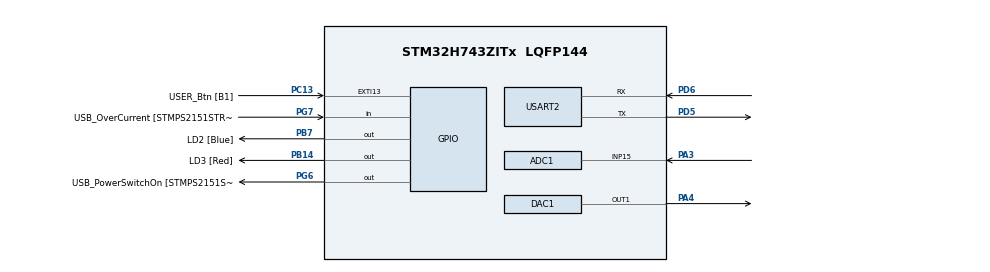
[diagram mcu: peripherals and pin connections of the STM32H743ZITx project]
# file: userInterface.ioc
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ADC1.Channel-28\#ChannelRegularConversion=ADC_CHANNEL_15
ADC1.NbrOfConversionFlag=1
ADC1.OffsetNumber-28\#ChannelRegularConversion=ADC_OFFSET_NONE
ADC1.Rank-28\#ChannelRegularConversion=1
ADC1.Resolution=ADC_RESOLUTION_8B
ADC1.SamplingTime-28\#ChannelRegularConversion=ADC_SAMPLETIME_1CYCLE_5
ADC1.master=1
DAC1.DAC_Trigger-DAC_OUT1=DAC_TRIGGER_T6_TRGO
Dma.DAC1_CH1.0.Direction=DMA_MEMORY_TO_PERIPH
Dma.DAC1_CH1.0.EventEnable=DISABLE
Dma.DAC1_CH1.0.FIFOMode=DMA_FIFOMODE_ENABLE
Dma.DAC1_CH1.0.FIFOThreshold=DMA_FIFO_THRESHOLD_FULL
Dma.DAC1_CH1.0.Instance=DMA1_Stream0
Dma.DAC1_CH1.0.MemBurst=DMA_MBURST_SINGLE
Dma.DAC1_CH1.0.MemDataAlignment=DMA_MDATAALIGN_HALFWORD
Dma.DAC1_CH1.0.MemInc=DMA_MINC_ENABLE
Dma.DAC1_CH1.0.Mode=DMA_CIRCULAR
Dma.DAC1_CH1.0.PeriphBurst=DMA_PBURST_SINGLE
Dma.DAC1_CH1.0.PeriphDataAlignment=DMA_PDATAALIGN_HALFWORD
Dma.DAC1_CH1.0.PeriphInc=DMA_PINC_DISABLE
Dma.DAC1_CH1.0.Polarity=HAL_DMAMUX_REQ_GEN_RISING
Dma.DAC1_CH1.0.Priority=DMA_PRIORITY_LOW
Dma.DAC1_CH1.0.RequestNumber=1
Dma.DAC1_CH1.0.SyncEnable=DISABLE
Dma.DAC1_CH1.0.SyncPolarity=HAL_DMAMUX_SYNC_NO_EVENT
Dma.DAC1_CH1.0.SyncRequestNumber=1
Dma.Request0=DAC1_CH1
FREERTOS.Queues01=queueCLI,32,uint8_t,0,Dynamic,NULL,NULL
FREERTOS.Tasks01=defaultTask,0,128,StartDefaultTask,Default,NULL,Dynamic,NULL,NULL;consoleTask,-2,128,StartConsoleTask,As weak,NULL,Dynamic,NULL,NULL;adc3Task,0,128,StartAdc1Task,As weak,NULL,Dynamic,NULL,NULL;dac1Task,-2,256,StartDac1Task,As weak,NULL,Dynamic,NULL,NULL
FREERTOS.configCHECK_FOR_STACK_OVERFLOW=1
FREERTOS.configUSE_MALLOC_FAILED_HOOK=1
Mcu.Family=STM32H7
Mcu.Name=STM32H743ZITx
Mcu.Package=LQFP144
NVIC.DMA1_Stream0_IRQn=true\:5\:0\:false\:false\:true\:true\:false
NVIC.PriorityGroup=NVIC_PRIORITYGROUP_4
NVIC.TIM1_UP_IRQn=true\:0\:0\:false\:false\:true\:false\:false
NVIC.TimeBase=TIM1_UP_IRQn
NVIC.TimeBaseIP=TIM1
NVIC.USART2_IRQn=true\:5\:0\:false\:false\:true\:true\:true
PA3.Signal=ADCx_INP15
PA4.Signal=COMP_DAC11_group
PB14.GPIO_Label=LD3 [Red]
PB14.Signal=GPIO_Output
PB7.GPIO_Label=LD2 [Blue]
PB7.Signal=GPIO_Output
PC13.GPIO_Label=USER_Btn [B1]
PC13.Signal=GPXTI13
PC3_C.Signal=ADC3_INP1
PD5.Mode=Asynchronous
PD5.Signal=USART2_TX
PD6.Mode=Asynchronous
PD6.Signal=USART2_RX
PG6.GPIO_Label=USB_PowerSwitchOn [STMPS2151STR_EN]
PG6.Signal=GPIO_Output
PG7.GPIO_Label=USB_OverCurrent [STMPS2151STR_FAULT]
PG7.Signal=GPIO_Input
ProjectManager.HeapSize=0x200
ProjectManager.StackSize=0x400
ProjectManager.TargetToolchain=TrueSTUDIO
RCC.48MHZClocksFreq_Value=24000000
RCC.ADCFreq_Value=129000000
RCC.AHBFreq_Value=216000000
RCC.APB1CLKDivider=RCC_HCLK_DIV4
RCC.APB1Freq_Value=80000000
RCC.APB1TimFreq_Value=108000000
RCC.APB2CLKDivider=RCC_HCLK_DIV2
RCC.APB2Freq_Value=80000000
RCC.APB2TimFreq_Value=216000000
RCC.APB3Freq_Value=80000000
RCC.APB4Freq_Value=80000000
RCC.CortexFreq_Value=80000000
RCC.DIVM1=4
RCC.DIVN1=10
RCC.DIVQ1=4
RCC.HCLKFreq_Value=80000000
RCC.HSE_VALUE=8000000
RCC.HSI_VALUE=64000000
RCC.PLLM=25
RCC.PLLMUL=RCC_PLL_MUL9
RCC.PLLN=432
RCC.PLLQ=9
RCC.PRESCALERUSB=RCC_USBCLKSOURCE_PLL_DIV1_5
RCC.SYSCLKFreq_VALUE=80000000
RCC.SYSCLKSource=RCC_SYSCLKSOURCE_PLLCLK
RCC.SYSCLKSourceVirtual=RCC_SYSCLKSOURCE_PLLCLK
RCC.USBFreq_Value=40000000
RCC.VCOOutputFreq_Value=432000000
SH.ADCx_INP15.0=ADC1_INP15,IN15-Single-Ended
SH.COMP_DAC11_group.0=DAC1_OUT1,DAC_OUT1
TIM6.Period=32
TIM6.TIM_MasterOutputTrigger=TIM_TRGO_UPDATE
USART2.VirtualMode-Asynchronous=VM_ASYNC
VP_FREERTOS_VS_ENABLE.Mode=Enabled
VP_SYS_VS_tim1.Mode=TIM1
VP_TIM6_VS_ClockSourceINT.Mode=Enable_Timer
board=NUCLEO-H743ZI

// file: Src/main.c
/**
  ******************************************************************************
  * @file           : main.c
  * @brief          : Main program body
  ******************************************************************************
  * This notice applies to any and all portions of this file
  * that are not between comment pairs USER CODE BEGIN and
  * USER CODE END. Other portions of this file, whether
  * inserted by the user or by software development tools
  * are owned by their respective copyright owners.
  *
  * Copyright (c) 2018 STMicroelectronics International N.V.
  * All rights reserved.
  *
  * Redistribution and use in source and binary forms, with or without
  * modification, are permitted, provided that the following conditions are met:
  *
  * 1. Redistribution of source code must retain the above copyright notice,
  *    this list of conditions and the following disclaimer.
  * 2. Redistributions in binary form must reproduce the above copyright notice,
  *    this list of conditions and the following disclaimer in the documentation
  *    and/or other materials provided with the distribution.
  * 3. Neither the name of STMicroelectronics nor the names of other
  *    contributors to this software may be used to endorse or promote products
  *    derived from this software without specific written permission.
  * 4. This software, including modifications and/or derivative works of this
  *    software, must execute solely and exclusively on microcontroller or
  *    microprocessor devices manufactured by or for STMicroelectronics.
  * 5. Redistribution and use of this software other than as permitted under
  *    this license is void and will automatically terminate your rights under
  *    this license.
  *
  * THIS SOFTWARE IS PROVIDED BY STMICROELECTRONICS AND CONTRIBUTORS "AS IS"
  * AND ANY EXPRESS, IMPLIED OR STATUTORY WARRANTIES, INCLUDING, BUT NOT
  * LIMITED TO, THE IMPLIED WARRANTIES OF MERCHANTABILITY, FITNESS FOR A
  * PARTICULAR PURPOSE AND NON-INFRINGEMENT OF THIRD PARTY INTELLECTUAL PROPERTY
  * RIGHTS ARE DISCLAIMED TO THE FULLEST EXTENT PERMITTED BY LAW. IN NO EVENT
  * SHALL STMICROELECTRONICS OR CONTRIBUTORS BE LIABLE FOR ANY DIRECT, INDIRECT,
  * INCIDENTAL, SPECIAL, EXEMPLARY, OR CONSEQUENTIAL DAMAGES (INCLUDING, BUT NOT
  * LIMITED TO, PROCUREMENT OF SUBSTITUTE GOODS OR SERVICES; LOSS OF USE, DATA,
  * OR PROFITS; OR BUSINESS INTERRUPTION) HOWEVER CAUSED AND ON ANY THEORY OF
  * LIABILITY, WHETHER IN CONTRACT, STRICT LIABILITY, OR TORT (INCLUDING
  * NEGLIGENCE OR OTHERWISE) ARISING IN ANY WAY OUT OF THE USE OF THIS SOFTWARE,
  * EVEN IF ADVISED OF THE POSSIBILITY OF SUCH DAMAGE.
  *
  ******************************************************************************
  */
#include "main.h"
#include "stm32h7xx_hal.h"
#include "cmsis_os.h"

/* USER CODE BEGIN Includes */
#include <stdio.h>
#include <string.h>
#include "consoleIO.h"

/* USER CODE END Includes */

ADC_HandleTypeDef hadc1;

DAC_HandleTypeDef hdac1;
DMA_HandleTypeDef hdma_dac1_ch1;

TIM_HandleTypeDef htim6;

UART_HandleTypeDef huart2;

osThreadId defaultTaskHandle;
osThreadId consoleTaskHandle;
osThreadId adc3TaskHandle;
osThreadId dac1TaskHandle;
osMessageQId queueCLIHandle;

/* USER CODE BEGIN PV */
/* Private variables ---------------------------------------------------------*/

/* USER CODE END PV */

void SystemClock_Config(void);
static void MX_GPIO_Init(void);
static void MX_DMA_Init(void);
static void MX_USART2_UART_Init(void);
static void MX_DAC1_Init(void);
static void MX_ADC1_Init(void);
static void MX_TIM6_Init(void);
void StartDefaultTask(void const * argument);
void StartConsoleTask(void const * argument);
void StartAdc1Task(void const * argument);
void StartDac1Task(void const * argument);

/* USER CODE BEGIN PFP */
/* Private function prototypes -----------------------------------------------*/

/* USER CODE END PFP */

int main(void)
{

  /* MCU Configuration----------------------------------------------------------*/

  /* Reset of all peripherals, Initializes the Flash interface and the Systick. */
  HAL_Init();

  /* USER CODE BEGIN Init */
	consoleInit();

  /* USER CODE END Init */

  /* Configure the system clock */
  SystemClock_Config();

  /* Initialize all configured peripherals */
  MX_GPIO_Init();
  MX_DMA_Init();
  MX_USART2_UART_Init();
  MX_DAC1_Init();
  MX_ADC1_Init();
  MX_TIM6_Init();
  /* USER CODE BEGIN 2 */
	StartConsoleIO();

  /* USER CODE END 2 */

  /* Create the thread(s) */
  /* definition and creation of defaultTask */
  osThreadDef(defaultTask, StartDefaultTask, osPriorityNormal, 0, 128);
  defaultTaskHandle = osThreadCreate(osThread(defaultTask), NULL);

  /* definition and creation of consoleTask */
  osThreadDef(consoleTask, StartConsoleTask, osPriorityLow, 0, 128);
  consoleTaskHandle = osThreadCreate(osThread(consoleTask), NULL);

  /* definition and creation of adc3Task */
  osThreadDef(adc3Task, StartAdc1Task, osPriorityNormal, 0, 128);
  adc3TaskHandle = osThreadCreate(osThread(adc3Task), NULL);

  /* definition and creation of dac1Task */
  osThreadDef(dac1Task, StartDac1Task, osPriorityLow, 0, 256);
  dac1TaskHandle = osThreadCreate(osThread(dac1Task), NULL);

  /* Create the queue(s) */
  /* definition and creation of queueCLI */
/* what about the sizeof here??? cd native code */
  osMessageQDef(queueCLI, 32, uint8_t);
  queueCLIHandle = osMessageCreate(osMessageQ(queueCLI), NULL);

  /* Start scheduler */
  osKernelStart();

  /* We should never get here as control is now taken by the scheduler */

  /* Infinite loop */
	while (1)
	{

	}

}

void SystemClock_Config(void)
{

  RCC_OscInitTypeDef RCC_OscInitStruct;
  RCC_ClkInitTypeDef RCC_ClkInitStruct;
  RCC_PeriphCLKInitTypeDef PeriphClkInitStruct;

    /**Supply configuration update enable
    */
  MODIFY_REG(PWR->CR3, PWR_CR3_SCUEN, 0);

    /**Configure the main internal regulator output voltage
    */
  __HAL_PWR_VOLTAGESCALING_CONFIG(PWR_REGULATOR_VOLTAGE_SCALE3);

  while ((PWR->D3CR & (PWR_D3CR_VOSRDY)) != PWR_D3CR_VOSRDY)
  {

  }
    /**Macro to configure the PLL clock source
    */
  __HAL_RCC_PLL_PLLSOURCE_CONFIG(RCC_PLLSOURCE_HSI);

    /**Initializes the CPU, AHB and APB busses clocks
    */
  RCC_OscInitStruct.OscillatorType = RCC_OSCILLATORTYPE_HSI;
  RCC_OscInitStruct.HSIState = RCC_HSI_DIV1;
  RCC_OscInitStruct.HSICalibrationValue = 16;
  RCC_OscInitStruct.PLL.PLLState = RCC_PLL_ON;
  RCC_OscInitStruct.PLL.PLLSource = RCC_PLLSOURCE_HSI;
  RCC_OscInitStruct.PLL.PLLM = 4;
  RCC_OscInitStruct.PLL.PLLN = 10;
  RCC_OscInitStruct.PLL.PLLP = 2;
  RCC_OscInitStruct.PLL.PLLQ = 4;
  RCC_OscInitStruct.PLL.PLLR = 2;
  RCC_OscInitStruct.PLL.PLLRGE = RCC_PLL1VCIRANGE_3;
  RCC_OscInitStruct.PLL.PLLVCOSEL = RCC_PLL1VCOMEDIUM;
  RCC_OscInitStruct.PLL.PLLFRACN = 0;
  if (HAL_RCC_OscConfig(&RCC_OscInitStruct) != HAL_OK)
  {
    _Error_Handler(__FILE__, __LINE__);
  }

    /**Initializes the CPU, AHB and APB busses clocks
    */
  RCC_ClkInitStruct.ClockType = RCC_CLOCKTYPE_HCLK|RCC_CLOCKTYPE_SYSCLK
                              |RCC_CLOCKTYPE_PCLK1|RCC_CLOCKTYPE_PCLK2
                              |RCC_CLOCKTYPE_D3PCLK1|RCC_CLOCKTYPE_D1PCLK1;
  RCC_ClkInitStruct.SYSCLKSource = RCC_SYSCLKSOURCE_PLLCLK;
  RCC_ClkInitStruct.SYSCLKDivider = RCC_SYSCLK_DIV1;
  RCC_ClkInitStruct.AHBCLKDivider = RCC_HCLK_DIV1;
  RCC_ClkInitStruct.APB3CLKDivider = RCC_APB3_DIV1;
  RCC_ClkInitStruct.APB1CLKDivider = RCC_APB1_DIV1;
  RCC_ClkInitStruct.APB2CLKDivider = RCC_APB2_DIV1;
  RCC_ClkInitStruct.APB4CLKDivider = RCC_APB4_DIV1;

  if (HAL_RCC_ClockConfig(&RCC_ClkInitStruct, FLASH_LATENCY_1) != HAL_OK)
  {
    _Error_Handler(__FILE__, __LINE__);
  }

  PeriphClkInitStruct.PeriphClockSelection = RCC_PERIPHCLK_USART2|RCC_PERIPHCLK_ADC;
  PeriphClkInitStruct.PLL2.PLL2M = 32;
  PeriphClkInitStruct.PLL2.PLL2N = 129;
  PeriphClkInitStruct.PLL2.PLL2P = 2;
  PeriphClkInitStruct.PLL2.PLL2Q = 2;
  PeriphClkInitStruct.PLL2.PLL2R = 2;
  PeriphClkInitStruct.PLL2.PLL2RGE = RCC_PLL2VCIRANGE_1;
  PeriphClkInitStruct.PLL2.PLL2VCOSEL = RCC_PLL2VCOWIDE;
  PeriphClkInitStruct.PLL2.PLL2FRACN = 0;
  PeriphClkInitStruct.Usart234578ClockSelection = RCC_USART234578CLKSOURCE_D2PCLK1;
  PeriphClkInitStruct.AdcClockSelection = RCC_ADCCLKSOURCE_PLL2;
  if (HAL_RCCEx_PeriphCLKConfig(&PeriphClkInitStruct) != HAL_OK)
  {
    _Error_Handler(__FILE__, __LINE__);
  }

    /**Configure the Systick interrupt time
    */
  HAL_SYSTICK_Config(SystemCoreClock/1000);

    /**Configure the Systick
    */
  HAL_SYSTICK_CLKSourceConfig(SYSTICK_CLKSOURCE_HCLK);

  /* SysTick_IRQn interrupt configuration */
  HAL_NVIC_SetPriority(SysTick_IRQn, 15, 0);
}

/* ADC1 init function */
static void MX_ADC1_Init(void)
{

  ADC_MultiModeTypeDef multimode;
  ADC_ChannelConfTypeDef sConfig;

    /**Common config
    */
  hadc1.Instance = ADC1;
  hadc1.Init.ClockPrescaler = ADC_CLOCK_ASYNC_DIV1;
  hadc1.Init.Resolution = ADC_RESOLUTION_8B;
  hadc1.Init.ScanConvMode = ADC_SCAN_DISABLE;
  hadc1.Init.EOCSelection = ADC_EOC_SINGLE_CONV;
  hadc1.Init.LowPowerAutoWait = DISABLE;
  hadc1.Init.ContinuousConvMode = DISABLE;
  hadc1.Init.NbrOfConversion = 1;
  hadc1.Init.DiscontinuousConvMode = DISABLE;
  hadc1.Init.NbrOfDiscConversion = 1;
  hadc1.Init.ExternalTrigConv = ADC_SOFTWARE_START;
  hadc1.Init.ExternalTrigConvEdge = ADC_EXTERNALTRIGCONVEDGE_NONE;
  hadc1.Init.ConversionDataManagement = ADC_CONVERSIONDATA_DR;
  hadc1.Init.Overrun = ADC_OVR_DATA_PRESERVED;
  hadc1.Init.LeftBitShift = ADC_LEFTBITSHIFT_NONE;
  hadc1.Init.BoostMode = ENABLE;
  hadc1.Init.OversamplingMode = DISABLE;
  if (HAL_ADC_Init(&hadc1) != HAL_OK)
  {
    _Error_Handler(__FILE__, __LINE__);
  }

    /**Configure the ADC multi-mode
    */
  multimode.Mode = ADC_MODE_INDEPENDENT;
  if (HAL_ADCEx_MultiModeConfigChannel(&hadc1, &multimode) != HAL_OK)
  {
    _Error_Handler(__FILE__, __LINE__);
  }

    /**Configure Regular Channel
    */
  sConfig.Channel = ADC_CHANNEL_15;
  sConfig.Rank = ADC_REGULAR_RANK_1;
  sConfig.SamplingTime = ADC_SAMPLETIME_1CYCLE_5;
  sConfig.SingleDiff = ADC_SINGLE_ENDED;
  sConfig.OffsetNumber = ADC_OFFSET_NONE;
  sConfig.Offset = 0;
  if (HAL_ADC_ConfigChannel(&hadc1, &sConfig) != HAL_OK)
  {
    _Error_Handler(__FILE__, __LINE__);
  }

}

/* DAC1 init function */
static void MX_DAC1_Init(void)
{

  DAC_ChannelConfTypeDef sConfig;

    /**DAC Initialization
    */
  hdac1.Instance = DAC1;
  if (HAL_DAC_Init(&hdac1) != HAL_OK)
  {
    _Error_Handler(__FILE__, __LINE__);
  }

    /**DAC channel OUT1 config
    */
  sConfig.DAC_SampleAndHold = DAC_SAMPLEANDHOLD_DISABLE;
  sConfig.DAC_Trigger = DAC_TRIGGER_T6_TRGO;
  sConfig.DAC_OutputBuffer = DAC_OUTPUTBUFFER_ENABLE;
  sConfig.DAC_ConnectOnChipPeripheral = DAC_CHIPCONNECT_DISABLE;
  sConfig.DAC_UserTrimming = DAC_TRIMMING_FACTORY;
  if (HAL_DAC_ConfigChannel(&hdac1, &sConfig, DAC_CHANNEL_1) != HAL_OK)
  {
    _Error_Handler(__FILE__, __LINE__);
  }

}

/* TIM6 init function */
static void MX_TIM6_Init(void)
{

  TIM_MasterConfigTypeDef sMasterConfig;

  htim6.Instance = TIM6;
  htim6.Init.Prescaler = 0;
  htim6.Init.CounterMode = TIM_COUNTERMODE_UP;
  htim6.Init.Period = 32;
  htim6.Init.AutoReloadPreload = TIM_AUTORELOAD_PRELOAD_DISABLE;
  if (HAL_TIM_Base_Init(&htim6) != HAL_OK)
  {
    _Error_Handler(__FILE__, __LINE__);
  }

  sMasterConfig.MasterOutputTrigger = TIM_TRGO_UPDATE;
  sMasterConfig.MasterSlaveMode = TIM_MASTERSLAVEMODE_DISABLE;
  if (HAL_TIMEx_MasterConfigSynchronization(&htim6, &sMasterConfig) != HAL_OK)
  {
    _Error_Handler(__FILE__, __LINE__);
  }

}

/* USART2 init function */
static void MX_USART2_UART_Init(void)
{

  huart2.Instance = USART2;
  huart2.Init.BaudRate = 115200;
  huart2.Init.WordLength = UART_WORDLENGTH_8B;
  huart2.Init.StopBits = UART_STOPBITS_1;
  huart2.Init.Parity = UART_PARITY_NONE;
  huart2.Init.Mode = UART_MODE_TX_RX;
  huart2.Init.HwFlowCtl = UART_HWCONTROL_NONE;
  huart2.Init.OverSampling = UART_OVERSAMPLING_16;
  huart2.Init.OneBitSampling = UART_ONE_BIT_SAMPLE_DISABLE;
  huart2.Init.Prescaler = UART_PRESCALER_DIV1;
  huart2.Init.FIFOMode = UART_FIFOMODE_DISABLE;
  huart2.Init.TXFIFOThreshold = UART_TXFIFO_THRESHOLD_1_8;
  huart2.Init.RXFIFOThreshold = UART_RXFIFO_THRESHOLD_1_8;
  huart2.AdvancedInit.AdvFeatureInit = UART_ADVFEATURE_NO_INIT;
  if (HAL_UART_Init(&huart2) != HAL_OK)
  {
    _Error_Handler(__FILE__, __LINE__);
  }

}

static void MX_DMA_Init(void)
{
  /* DMA controller clock enable */
  __HAL_RCC_DMA1_CLK_ENABLE();

  /* DMA interrupt init */
  /* DMA1_Stream0_IRQn interrupt configuration */
  HAL_NVIC_SetPriority(DMA1_Stream0_IRQn, 5, 0);
  HAL_NVIC_EnableIRQ(DMA1_Stream0_IRQn);

}

/** Configure pins as
        * Analog
        * Input
        * Output
        * EVENT_OUT
        * EXTI
     PC3_C   ------> ADC3_INP1
*/
static void MX_GPIO_Init(void)
{

  GPIO_InitTypeDef GPIO_InitStruct;

  /* GPIO Ports Clock Enable */
  __HAL_RCC_GPIOC_CLK_ENABLE();
  __HAL_RCC_GPIOA_CLK_ENABLE();
  __HAL_RCC_GPIOB_CLK_ENABLE();
  __HAL_RCC_GPIOG_CLK_ENABLE();
  __HAL_RCC_GPIOD_CLK_ENABLE();

  /*Configure GPIO pin Output Level */
  HAL_GPIO_WritePin(GPIOB, LD3_Pin|LD2_Pin, GPIO_PIN_RESET);

  /*Configure GPIO pin Output Level */
  HAL_GPIO_WritePin(USB_PowerSwitchOn_GPIO_Port, USB_PowerSwitchOn_Pin, GPIO_PIN_RESET);

  /*Configure GPIO pin : USER_Btn_Pin */
  GPIO_InitStruct.Pin = USER_Btn_Pin;
  GPIO_InitStruct.Mode = GPIO_MODE_IT_RISING;
  GPIO_InitStruct.Pull = GPIO_NOPULL;
  HAL_GPIO_Init(USER_Btn_GPIO_Port, &GPIO_InitStruct);

  /*Configure GPIO pins : LD3_Pin LD2_Pin */
  GPIO_InitStruct.Pin = LD3_Pin|LD2_Pin;
  GPIO_InitStruct.Mode = GPIO_MODE_OUTPUT_PP;
  GPIO_InitStruct.Pull = GPIO_NOPULL;
  GPIO_InitStruct.Speed = GPIO_SPEED_FREQ_LOW;
  HAL_GPIO_Init(GPIOB, &GPIO_InitStruct);

  /*Configure GPIO pin : USB_PowerSwitchOn_Pin */
  GPIO_InitStruct.Pin = USB_PowerSwitchOn_Pin;
  GPIO_InitStruct.Mode = GPIO_MODE_OUTPUT_PP;
  GPIO_InitStruct.Pull = GPIO_NOPULL;
  GPIO_InitStruct.Speed = GPIO_SPEED_FREQ_LOW;
  HAL_GPIO_Init(USB_PowerSwitchOn_GPIO_Port, &GPIO_InitStruct);

  /*Configure GPIO pin : USB_OverCurrent_Pin */
  GPIO_InitStruct.Pin = USB_OverCurrent_Pin;
  GPIO_InitStruct.Mode = GPIO_MODE_INPUT;
  GPIO_InitStruct.Pull = GPIO_NOPULL;
  HAL_GPIO_Init(USB_OverCurrent_GPIO_Port, &GPIO_InitStruct);

  /*AnalogSwitch Config */
  HAL_SYSCFG_AnalogSwitchConfig(SYSCFG_SWITCH_PC3, SYSCFG_SWITCH_PC3_OPEN);

}

/* StartDefaultTask function */
void StartDefaultTask(void const * argument)
{

  /* USER CODE BEGIN 5 */
	/* Infinite loop */
	printf("StartDefaultTask\n");
	vTaskDelay(100);
	for(;;)
	{
		osDelay(1);
	}
  /* USER CODE END 5 */
}

/* StartConsoleTask function */
__weak void StartConsoleTask(void const * argument)
{
	for(;;)
	{
		osDelay(1);
	}
}

/* StartAdc1Task function */
__weak void StartAdc1Task(void const * argument)
{
  for(;;)
  {
    osDelay(1);
  }
}

/* StartDac1Task function */
__weak void StartDac1Task(void const * argument)
{
  for(;;)
  {
    osDelay(1);
  }
}

void HAL_TIM_PeriodElapsedCallback(TIM_HandleTypeDef *htim)
{
  if (htim->Instance == TIM1) {
    HAL_IncTick();
  }
}

void _Error_Handler(char *file, int line)
{
	while(1)
	{
	}
}

/************************ (C) COPYRIGHT STMicroelectronics *****END OF FILE****/
